# ATxmega128A1U device description
Architecture: AVR8_XMEGA; Family: AVR XMEGA
Registers are 8-bit, access not given, no defined reset value unless marked. A register's access mark holds for its fields unless they carry their own. Offsets are from the block's base; [hi:lo] are bit positions; {n}, {i} and the like mark numbered series; 'fields as' and 'values as' point back to an identical list.

## AWEX — Advanced Waveform Extension
Instances: AWEXC 0x880, AWEXE 0xA80
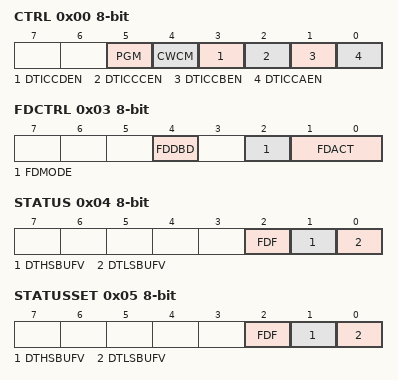
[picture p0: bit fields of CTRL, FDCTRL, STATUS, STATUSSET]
0x00 CTRL — Control Register
  [5] PGM — Pattern Generation Mode
  [4] CWCM — Common Waveform Channel Mode
  [3] DTICCDEN — Dead Time Insertion Compare Channel D Enable
  [2] DTICCCEN — Dead Time Insertion Compare Channel C Enable
  [1] DTICCBEN — Dead Time Insertion Compare Channel B Enable
  [0] DTICCAEN — Dead Time Insertion Compare Channel A Enable
0x02 FDEMASK — Fault Detection Event Mask
0x03 FDCTRL — Fault Detection Control Register
  [4] FDDBD — Fault Detect on Disable Break Disable
  [2] FDMODE — Fault Detect Mode
  [1:0] FDACT — Fault Detect Action
    0=NONE (No Fault Protection); 1=CLEAROE (Clear Output Enable Bits); 3=CLEARDIR (Clear I/O Port Direction Bits)
0x04 STATUS
  [2] FDF — Fault Detect Flag
  [1] DTHSBUFV — Dead Time High Side Buffer Valid
  [0] DTLSBUFV — Dead Time Low Side Buffer Valid
0x05 STATUSSET
  fields as STATUS
0x06 DTBOTH — Dead Time Both Sides
0x07 DTBOTHBUF — Dead Time Both Sides Buffer
0x08 DTLS — Dead Time Low Side
0x09 DTHS — Dead Time High Side
0x0A DTLSBUF — Dead Time Low Side Buffer
0x0B DTHSBUF — Dead Time High Side Buffer
0x0C OUTOVEN — Output Override Enable

## HIRES — High-Resolution Extension
Instances: HIRESC 0x890, HIRESD 0x990, HIRESE 0xA90, HIRESF 0xB90
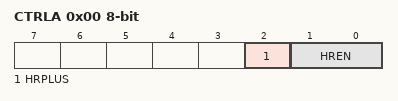
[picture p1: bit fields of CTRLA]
0x00 CTRLA — Control Register
  [2] HRPLUS — High Resolution Plus
  [1:0] HREN — High Resolution Enable
    0=NONE (No Fault Protection); 1=TC0 (Enable High Resolution on Timer/Counter 0); 2=TC1 (Enable High Resolution on Timer/Counter 1); 3=BOTH (Enable High Resolution both Timer/Counters)

## USART — Universal Synchronous/Asynchronous Receiver/Transmitter
Instances: USARTC0 0x8A0, USARTC1 0x8B0, USARTD0 0x9A0, USARTD1 0x9B0, USARTE0 0xAA0, USARTE1 0xAB0, USARTF0 0xBA0, USARTF1 0xBB0
0x00 DATA
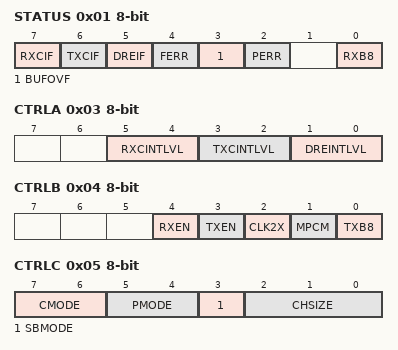
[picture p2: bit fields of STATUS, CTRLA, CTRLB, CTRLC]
0x01 STATUS
  [7] RXCIF — Receive Interrupt Flag
  [6] TXCIF — Transmit Interrupt Flag
  [5] DREIF — Data Register Empty Flag
  [4] FERR — Frame Error
  [3] BUFOVF — Buffer Overflow
  [2] PERR — Parity Error
  [0] RXB8 — Receive Bit 8
0x03 CTRLA — Control Register A
  [all] fields
    0=OFF (Interrupt Disabled); 1=LO (Low Level); 2=MED (Medium Level); 3=HI (High Level)
  [5:4] RXCINTLVL — Receive Interrupt Level
  [3:2] TXCINTLVL — Transmit Interrupt Level
  [1:0] DREINTLVL — Data Register Empty Interrupt Level
0x04 CTRLB — Control Register B
  [4] RXEN — Receiver Enable
  [3] TXEN — Transmitter Enable
  [2] CLK2X — Double transmission speed
  [1] MPCM — Multi-processor Communication Mode
  [0] TXB8 — Transmit bit 8
0x05 CTRLC — Control Register C
  [7:6] CMODE — Communication Mode
    0=ASYNCHRONOUS (Asynchronous Mode); 1=SYNCHRONOUS (Synchronous Mode); 2=IRDA (IrDA Mode); 3=MSPI (Master SPI Mode)
  [5:4] PMODE — Parity Mode
    0=DISABLED (No Parity); 2=EVEN (Even Parity); 3=ODD (Odd Parity)
  [3] SBMODE — Stop Bit Mode
  [2:0] CHSIZE — Character Size
    {v}={v+5}BIT (Character size: {v+5} bit) (v=0..3); 7=9BIT (Character size: 9 bit)
0x06 BAUDCTRLA — Baud Rate Control Register A
  [7:0] BSEL — Baud Rate Selection Bits [7:0]
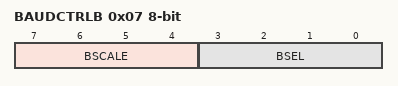
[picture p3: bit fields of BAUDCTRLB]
0x07 BAUDCTRLB — Baud Rate Control Register B
  [7:4] BSCALE — Baud Rate Scale
  [3:0] BSEL — Baud Rate Selection bits[11:8]

## SPI — Serial Peripheral Interface
Instances: SPIC 0x8C0, SPID 0x9C0, SPIE 0xAC0, SPIF 0xBC0
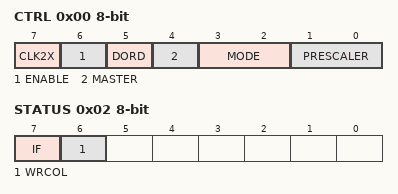
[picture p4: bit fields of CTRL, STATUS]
0x00 CTRL — Control Register
  [7] CLK2X — Enable Double Speed
  [6] ENABLE — Enable Module
  [5] DORD — Data Order Setting
  [4] MASTER — Master Operation Enable
  [3:2] MODE — SPI Mode
    {v}=SPI Mode {v} (v=0..3)
  [1:0] PRESCALER
    0=DIV4 (System Clock / 4); 1=DIV16 (System Clock / 16); 2=DIV64 (System Clock / 64); 3=DIV128 (System Clock / 128)
0x01 INTCTRL — Interrupt Control Register
  [1:0] INTLVL — Interrupt level
    0=OFF (Interrupt Disabled); 1=LO (Low Level); 2=MED (Medium Level); 3=HI (High Level)
0x02 STATUS
  [7] IF — Interrupt Flag
  [6] WRCOL — Write Collision
0x03 DATA
